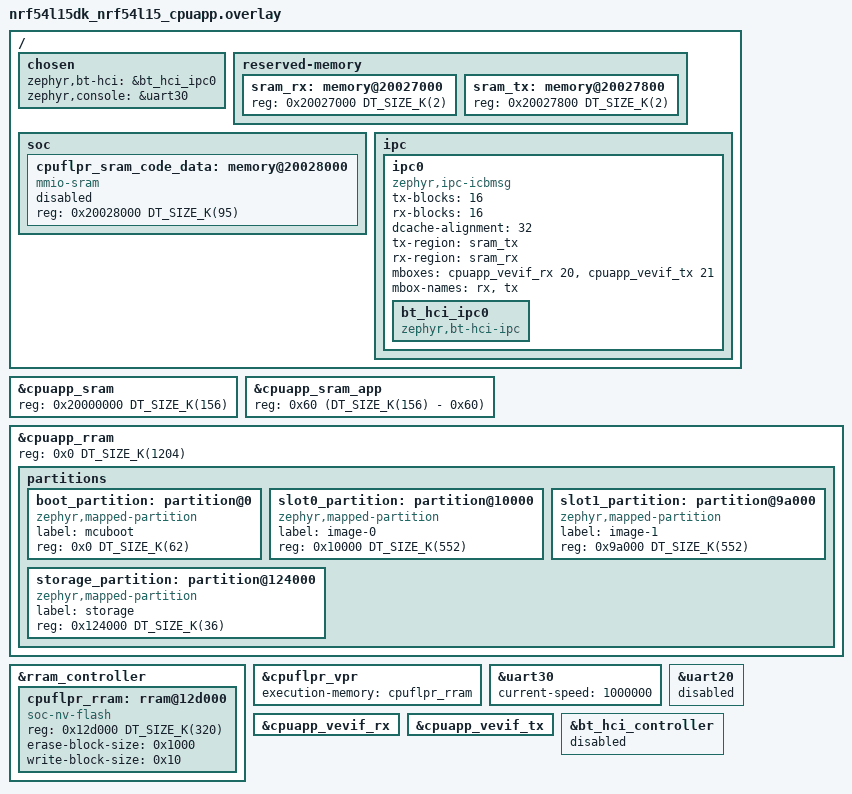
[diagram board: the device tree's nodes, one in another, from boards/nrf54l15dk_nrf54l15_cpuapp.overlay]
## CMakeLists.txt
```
# SPDX-License-Identifier: Apache-2.0

cmake_minimum_required(VERSION 3.28.0)
find_package(Zephyr REQUIRED HINTS $ENV{ZEPHYR_BASE})
project(central_hr)

FILE(GLOB app_sources src/*.c)
target_sources(app PRIVATE ${app_sources})

zephyr_library_include_directories(${ZEPHYR_BASE}/samples/bluetooth)
```

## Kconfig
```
# Copyright 2024 Nordic Semiconductor ASA
# SPDX-License-Identifier: Apache-2.0

if "$(FILE_SUFFIX)" = "extended"

# Increase Advertising Data Length, as Complete Local Name too needs to be
# placed in the AUX_ADV_IND PDU compared to when it is placed in ADV_SCAN_IND
# PDU in the case of legacy advertising.
configdefault BT_CTLR_SCAN_DATA_LEN_MAX
	default 36

endif


if "$(FILE_SUFFIX)" = "phy_coded"

# Increase Advertising Data Length, as Complete Local Name too needs to be
# placed in the AUX_ADV_IND PDU compared to when it is placed in ADV_SCAN_IND
# PDU in the case of legacy advertising.
configdefault BT_CTLR_SCAN_DATA_LEN_MAX
	default 36

configdefault BT_CTLR_PHY_CODED
	default y

endif


source "Kconfig"
```

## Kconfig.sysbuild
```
# Copyright 2023-2024 Nordic Semiconductor ASA
# SPDX-License-Identifier: Apache-2.0

source "share/sysbuild/Kconfig"

config NET_CORE_BOARD
	string
	default "nrf5340dk/nrf5340/cpunet" if "$(BOARD)" = "nrf5340dk"
	default "nrf5340_audio_dk/nrf5340/cpunet" if "$(BOARD)" = "nrf5340_audio_dk"
	default "nrf5340bsim_nrf5340_cpunet" if "$(BOARD)" = "nrf5340bsim_nrf5340_cpuapp"

config NET_CORE_IMAGE_HCI_IPC
	bool "HCI IPC image on network core"
	default y
	depends on NET_CORE_BOARD != ""
```

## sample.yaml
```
sample:
  name: Bluetooth Central HR
tests:
  sample.bluetooth.central_hr:
    arch_allow: x86
    harness: bluetooth
    tags: bluetooth
  sample.bluetooth.central_hr.minimal:
    harness: bluetooth
    platform_allow:
      - bbc_microbit
    integration_platforms:
      - bbc_microbit
    extra_args: CONF_FILE=prj_minimal.conf
    tags: bluetooth
  sample.bluetooth.central_hr.bt_ll_sw_split.extended:
    harness: bluetooth
    platform_allow:
      - nrf52_bsim
      - nrf52dk/nrf52832
      - nrf52840dk/nrf52840
    integration_platforms:
      - nrf52_bsim
      - nrf52dk/nrf52832
      - nrf52840dk/nrf52840
    extra_args: EXTRA_CONF_FILE=overlay-extended.conf
    tags: bluetooth
  sample.bluetooth.central_hr.multicore.bt_ll_sw_split.extended:
    harness: bluetooth
    platform_allow:
      - nrf5340bsim/nrf5340/cpuapp
      - nrf5340dk/nrf5340/cpuapp
    integration_platforms:
      - nrf5340bsim/nrf5340/cpuapp
      - nrf5340dk/nrf5340/cpuapp
    extra_args:
      - CONFIG_BT_EXT_ADV=y
    tags: bluetooth
    sysbuild: true
  sample.bluetooth.central_hr.bt_ll_sw_split.phy_coded:
    harness: bluetooth
    platform_allow:
      - nrf52_bsim
      - nrf52dk/nrf52832
      - nrf52840dk/nrf52840
    integration_platforms:
      - nrf52_bsim
      - nrf52dk/nrf52832
      - nrf52840dk/nrf52840
    extra_args: EXTRA_CONF_FILE=overlay-phy_coded.conf
    tags: bluetooth
  sample.bluetooth.central_hr.multicore.bt_ll_sw_split.phy_coded:
    harness: bluetooth
    platform_allow:
      - nrf5340bsim/nrf5340/cpuapp
      - nrf5340dk/nrf5340/cpuapp
    integration_platforms:
      - nrf5340bsim/nrf5340/cpuapp
      - nrf5340dk/nrf5340/cpuapp
    extra_args:
      - CONFIG_BT_EXT_ADV=y
      - CONFIG_BT_AUTO_PHY_CENTRAL_NONE=y
    tags: bluetooth
    sysbuild: true
```

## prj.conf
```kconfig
CONFIG_BT=y
CONFIG_LOG=y
CONFIG_BT_CENTRAL=y
CONFIG_BT_SMP=y
CONFIG_BT_GATT_CLIENT=y
```

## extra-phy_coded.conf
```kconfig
CONFIG_BT_EXT_ADV=y

# Enable Coded PHY support
CONFIG_BT_CTLR_PHY_CODED=y

# Disable auto PHY update, to switch to 2M PHY
CONFIG_BT_AUTO_PHY_CENTRAL_NONE=y

# Increase Scan Data Length, as Complete Local Name is placed in the
# AUX_ADV_IND PDU compared to when it is placed in ADV_SCAN_IND PDU in the case
# of legacy advertising.
CONFIG_BT_CTLR_SCAN_DATA_LEN_MAX=36
```

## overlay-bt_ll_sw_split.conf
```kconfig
# Configuration file to be used as an overlay to the hci_ipc sample for multi-core boards

CONFIG_BT_EXT_ADV=y

# Enable Coded PHY support
CONFIG_BT_CTLR_PHY_CODED=y

# Increase Advertising Data Length, as Complete Local Name too needs to be
# placed in the AUX_ADV_IND PDU compared to when it is placed in ADV_SCAN_IND
# PDU in the case of legacy advertising.
CONFIG_BT_CTLR_SCAN_DATA_LEN_MAX=36
```

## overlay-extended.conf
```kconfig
CONFIG_BT_EXT_ADV=y

# Increase Scan Data Length, as Complete Local Name is placed in the
# AUX_ADV_IND PDU compared to when it is placed in ADV_SCAN_IND PDU in the case
# of legacy advertising.
CONFIG_BT_CTLR_SCAN_DATA_LEN_MAX=36
```

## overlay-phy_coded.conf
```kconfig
CONFIG_BT_EXT_ADV=y

# Enable Coded PHY support
CONFIG_BT_CTLR_PHY_CODED=y

# Disable auto PHY update, to switch to 2M PHY
CONFIG_BT_AUTO_PHY_UPDATE=n

# Increase Scan Data Length, as Complete Local Name is placed in the
# AUX_ADV_IND PDU compared to when it is placed in ADV_SCAN_IND PDU in the case
# of legacy advertising.
CONFIG_BT_CTLR_SCAN_DATA_LEN_MAX=36
```

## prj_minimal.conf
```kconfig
CONFIG_BT=y
CONFIG_BT_SMP=y
CONFIG_BT_CENTRAL=y
CONFIG_BT_GATT_CLIENT=y

# Drivers and peripherals
CONFIG_I2C=n
CONFIG_WATCHDOG=n
CONFIG_PINCTRL=n
CONFIG_SPI=n
CONFIG_GPIO=n
CONFIG_SERIAL=n

# Power management
CONFIG_PM=n

# Interrupts
CONFIG_DYNAMIC_INTERRUPTS=n
CONFIG_IRQ_OFFLOAD=n

# Memory protection
CONFIG_THREAD_STACK_INFO=n
CONFIG_THREAD_CUSTOM_DATA=n
CONFIG_FPU=n

# Boot
CONFIG_BOOT_BANNER=n
CONFIG_BOOT_DELAY=0

# Console
CONFIG_CONSOLE=n
CONFIG_UART_CONSOLE=n
CONFIG_STDOUT_CONSOLE=n
CONFIG_PRINTK=n
CONFIG_EARLY_CONSOLE=n

# Build
CONFIG_SIZE_OPTIMIZATIONS=y

# ARM
CONFIG_ARM_MPU=n

# In order to correctly tune the stack sizes for the threads the following
# Configurations can enabled to print the current use:
# CONFIG_THREAD_NAME=y
# CONFIG_THREAD_ANALYZER=y
# CONFIG_THREAD_ANALYZER_AUTO=y
# CONFIG_THREAD_ANALYZER_RUN_UNLOCKED=y
# CONFIG_THREAD_ANALYZER_USE_PRINTK=y
# CONFIG_THREAD_ANALYZER_AUTO_INTERVAL=20
# CONFIG_CONSOLE=y
# CONFIG_UART_CONSOLE=y
# CONFIG_SERIAL=y
# CONFIG_PRINTK=y

# Example output of thread analyzer
# BT RX               : STACK: unused 576 usage 448 / 1024 (43 %); CPU: 0 %
# BT RX pri           : STACK: unused 260 usage 188 / 448 (41 %); CPU: 0 %
# BT ECC              : STACK: unused 256 usage 888 / 1144 (77 %); CPU: 1 %
# BT TX               : STACK: unused 296 usage 344 / 640 (53 %); CPU: 0 %
# thread_analyzer     : STACK: unused 128 usage 384 / 512 (75 %); CPU: 1 %
# sysworkq            : STACK: unused 856 usage 168 / 1024 (16 %); CPU: 0 %
# logging             : STACK: unused 232 usage 536 / 768 (69 %); CPU: 0 %
# idle 00             : STACK: unused 208 usage 48 / 256 (18 %); CPU: 97 %
# main                : STACK: unused 576 usage 448 / 1024 (43 %); CPU: 0 %
CONFIG_BT_RX_STACK_SIZE=1024
CONFIG_BT_HCI_TX_STACK_SIZE_WITH_PROMPT=y
CONFIG_BT_HCI_TX_STACK_SIZE=640
CONFIG_IDLE_STACK_SIZE=128
CONFIG_MAIN_STACK_SIZE=640
CONFIG_ISR_STACK_SIZE=1024

# Disable features not needed
CONFIG_TIMESLICING=n
CONFIG_COMMON_LIBC_MALLOC=n
CONFIG_LOG=n
CONFIG_ASSERT=n

# Disable Bluetooth features not needed
# CONFIG_BT_DEBUG_NONE=y
CONFIG_BT_ASSERT=n
CONFIG_BT_DATA_LEN_UPDATE=n
CONFIG_BT_PHY_UPDATE=n
CONFIG_BT_GATT_CACHING=n
CONFIG_BT_GATT_SERVICE_CHANGED=n
CONFIG_BT_GAP_PERIPHERAL_PREF_PARAMS=n
CONFIG_BT_SETTINGS_CCC_LAZY_LOADING=y
CONFIG_BT_HCI_VS=n
CONFIG_BT_CONN_DYNAMIC_CALLBACKS=n

# Disable Bluetooth controller features not needed
CONFIG_BT_CTLR_PRIVACY=n
CONFIG_BT_CTLR_PHY_2M=n
# The sample scans without duplicate filtering
CONFIG_BT_CTLR_DUP_FILTER_LEN=0

# Reduce Bluetooth buffers
CONFIG_BT_BUF_EVT_DISCARDABLE_COUNT=1
CONFIG_BT_BUF_EVT_DISCARDABLE_SIZE=45
CONFIG_BT_BUF_EVT_RX_COUNT=4

CONFIG_BT_L2CAP_TX_BUF_COUNT=2
CONFIG_BT_CTLR_RX_BUFFERS=1
CONFIG_BT_BUF_ACL_TX_COUNT=3
CONFIG_BT_BUF_ACL_TX_SIZE=27

# Limit the number of key slots in PSA Crypto core to reduce
# RAM footprint. Each key the Host uses lives for one operation only: at
# most one key pair, for generating the public key or a DH key, and one
# short-lived key of a pairing computation exist at a time, as nothing
# else in this configuration uses the key store. Three slots leave one
# to spare.
CONFIG_MBEDTLS_PSA_KEY_SLOT_COUNT=3

# This is required because otherwise there won't be
# __heap_start/__heap_end symbols defined in the build. This
# is due to Mbed TLS which at boot uses standard calloc/free
# functions and only after the initialization done from Zephyr
# it switches to its internal memory management functions.
CONFIG_COMMON_LIBC_MALLOC=y
```

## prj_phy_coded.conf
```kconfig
CONFIG_BT_EXT_ADV=y

# Disable auto PHY update, to switch to 2M PHY
CONFIG_BT_AUTO_PHY_UPDATE=n
```

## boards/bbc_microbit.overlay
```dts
/*
 * SPDX-FileCopyrightText: Copyright (c) 2026 Silicon Laboratories Inc.
 * SPDX-License-Identifier: Apache-2.0
 */

/* The sample does not use the accelerometer. With its node enabled the driver
 * is built in as soon as the sensor subsystem is on, which the clock
 * calibration turns on, and brings the I2C driver with it.
 */
&mma8653fc {
	status = "disabled";
};
```

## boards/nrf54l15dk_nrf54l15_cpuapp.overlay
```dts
/*
 * Copyright (c) 2026 Nordic Semiconductor ASA
 *
 * SPDX-License-Identifier: Apache-2.0
 */

/*
 * Must match samples/bluetooth/hci_ipc/boards/nrf54l15dk_nrf54l15_cpuflpr.overlay
 *
 * RRAM: 1204 (APP) + 320 (FLPR) = 1524KB
 * RAM:  156 (APP) + 4 (IPC) + 95 (FLPR) + 1 (unused) = 256KB
 */

/ {
	chosen {
		zephyr,bt-hci = &bt_hci_ipc0;
		zephyr,console = &uart30;
	};

	reserved-memory {
		sram_rx: memory@20027000 {
			reg = <0x20027000 DT_SIZE_K(2)>;
		};

		sram_tx: memory@20027800 {
			reg = <0x20027800 DT_SIZE_K(2)>;
		};
	};

	soc {
		cpuflpr_sram_code_data: memory@20028000 {
			compatible = "mmio-sram";
			reg = <0x20028000 DT_SIZE_K(95)>;
			ranges = <0x0 0x20028000 DT_SIZE_K(95)>;
			status = "reserved";
			#address-cells = <1>;
			#size-cells = <1>;
		};
	};

	ipc {
		ipc0: ipc0 {
			compatible = "zephyr,ipc-icbmsg";
			tx-blocks = <16>;
			rx-blocks = <16>;
			dcache-alignment = <32>;
			tx-region = <&sram_tx>;
			rx-region = <&sram_rx>;
			mboxes = <&cpuapp_vevif_rx 20>, <&cpuapp_vevif_tx 21>;
			mbox-names = "rx", "tx";
			status = "okay";

			bt_hci_ipc0: bt_hci_ipc0 {
				compatible = "zephyr,bt-hci-ipc";
				status = "okay";
			};
		};
	};
};

&cpuapp_sram {
	reg = <0x20000000 DT_SIZE_K(156)>;
	ranges = <0x0 0x20000000 DT_SIZE_K(156)>;
};

&cpuapp_sram_app {
	reg = <0x60 (DT_SIZE_K(156) - 0x60)>;
};

&cpuapp_rram {
	reg = <0x0 DT_SIZE_K(1204)>;
	ranges = <0x0 0x0 DT_SIZE_K(1204)>;

	/delete-node/ partitions;

	partitions {
		ranges;
		#address-cells = <1>;
		#size-cells = <1>;

		boot_partition: partition@0 {
			compatible = "zephyr,mapped-partition";
			label = "mcuboot";
			reg = <0x0 DT_SIZE_K(62)>;
		};

		slot0_partition: partition@10000 {
			compatible = "zephyr,mapped-partition";
			label = "image-0";
			reg = <0x10000 DT_SIZE_K(552)>;
		};

		slot1_partition: partition@9a000 {
			compatible = "zephyr,mapped-partition";
			label = "image-1";
			reg = <0x9a000 DT_SIZE_K(552)>;
		};

		storage_partition: partition@124000 {
			compatible = "zephyr,mapped-partition";
			label = "storage";
			reg = <0x124000 DT_SIZE_K(36)>;
		};
	};
};

&rram_controller {
	cpuflpr_rram: rram@12d000 {
		compatible = "soc-nv-flash";
		reg = <0x12d000 DT_SIZE_K(320)>;
		ranges = <0x0 0x12d000 DT_SIZE_K(320)>;
		erase-block-size = <0x1000>;
		write-block-size = <0x10>;
		#address-cells = <1>;
		#size-cells = <1>;
	};
};

&cpuflpr_vpr {
	status = "okay";
	execution-memory = <&cpuflpr_rram>;
	/*
	 * execution-memory = <&cpuflpr_sram_code_data>;
	 * source-memory = <&cpuflpr_rram>;
	 */
};

&uart30 {
	current-speed = <1000000>;
	status = "okay";
};

&uart20 {
	status = "disabled";
};

&cpuapp_vevif_rx {
	status = "okay";
};

&cpuapp_vevif_tx {
	status = "okay";
};

&bt_hci_controller {
	status = "disabled";
};
```

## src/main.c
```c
/* main.c - Application main entry point */

/*
 * Copyright (c) 2015-2016 Intel Corporation
 *
 * SPDX-License-Identifier: Apache-2.0
 */

#include <zephyr/types.h>
#include <stddef.h>
#include <errno.h>
#include <zephyr/kernel.h>
#include <zephyr/sys/printk.h>

#include <zephyr/bluetooth/bluetooth.h>
#include <zephyr/bluetooth/hci.h>
#include <zephyr/bluetooth/conn.h>
#include <zephyr/bluetooth/uuid.h>
#include <zephyr/bluetooth/gatt.h>
#include <zephyr/sys/byteorder.h>

static void start_scan(void);

static struct bt_conn *default_conn;

static struct bt_uuid_16 discover_uuid = BT_UUID_INIT_16(0);
static struct bt_gatt_discover_params discover_params;
static struct bt_gatt_subscribe_params subscribe_params;

uint64_t total_rx_count; /* This value is exposed to test code */

static uint8_t notify_func(struct bt_conn *conn,
			   struct bt_gatt_subscribe_params *params,
			   const void *data, uint16_t length)
{
	if (!data) {
		printk("[UNSUBSCRIBED]\n");
		params->value_handle = 0U;
		return BT_GATT_ITER_STOP;
	}

	printk("[NOTIFICATION] data %p length %u\n", data, length);

	total_rx_count++;

	return BT_GATT_ITER_CONTINUE;
}

static uint8_t discover_func(struct bt_conn *conn,
			     const struct bt_gatt_attr *attr,
			     struct bt_gatt_discover_params *params)
{
	int err;

	if (!attr) {
		printk("Discover complete\n");
		(void)memset(params, 0, sizeof(*params));
		return BT_GATT_ITER_STOP;
	}

	printk("[ATTRIBUTE] handle %u\n", attr->handle);

	if (!bt_uuid_cmp(discover_params.uuid, BT_UUID_HRS)) {
		memcpy(&discover_uuid, BT_UUID_HRS_MEASUREMENT, sizeof(discover_uuid));
		discover_params.uuid = &discover_uuid.uuid;
		discover_params.start_handle = attr->handle + 1;
		discover_params.type = BT_GATT_DISCOVER_CHARACTERISTIC;

		err = bt_gatt_discover(conn, &discover_params);
		if (err) {
			printk("Discover failed (err %d)\n", err);
		}
	} else if (!bt_uuid_cmp(discover_params.uuid,
				BT_UUID_HRS_MEASUREMENT)) {
		memcpy(&discover_uuid, BT_UUID_GATT_CCC, sizeof(discover_uuid));
		discover_params.uuid = &discover_uuid.uuid;
		discover_params.start_handle = attr->handle + 2;
		discover_params.type = BT_GATT_DISCOVER_DESCRIPTOR;
		subscribe_params.value_handle = bt_gatt_attr_value_handle(attr);

		err = bt_gatt_discover(conn, &discover_params);
		if (err) {
			printk("Discover failed (err %d)\n", err);
		}
	} else {
		subscribe_params.notify = notify_func;
		subscribe_params.value = BT_GATT_CCC_NOTIFY;
		subscribe_params.ccc_handle = attr->handle;

		err = bt_gatt_subscribe(conn, &subscribe_params);
		if (err && err != -EALREADY) {
			printk("Subscribe failed (err %d)\n", err);
		} else {
			printk("[SUBSCRIBED]\n");
		}

		return BT_GATT_ITER_STOP;
	}

	return BT_GATT_ITER_STOP;
}

static bool eir_found(struct bt_data *data, void *user_data)
{
	bt_addr_le_t *addr = user_data;
	int i;

	printk("[AD]: %u data_len %u\n", data->type, data->data_len);

	switch (data->type) {
	case BT_DATA_UUID16_SOME:
	case BT_DATA_UUID16_ALL:
		if (data->data_len % sizeof(uint16_t) != 0U) {
			printk("AD malformed\n");
			return true;
		}

		for (i = 0; i < data->data_len; i += sizeof(uint16_t)) {
			struct bt_conn_le_create_param *create_param;
			struct bt_le_conn_param *param;
			const struct bt_uuid *uuid;
			uint16_t u16;
			int err;

			memcpy(&u16, &data->data[i], sizeof(u16));
			uuid = BT_UUID_DECLARE_16(sys_le16_to_cpu(u16));
			if (bt_uuid_cmp(uuid, BT_UUID_HRS)) {
				continue;
			}

			err = bt_le_scan_stop();
			if (err) {
				printk("Stop LE scan failed (err %d)\n", err);
				continue;
			}

			printk("Creating connection with Coded PHY support\n");
			param = BT_LE_CONN_PARAM_DEFAULT;
			create_param = BT_CONN_LE_CREATE_CONN;
			create_param->options |= BT_CONN_LE_OPT_CODED;
			err = bt_conn_le_create(addr, create_param, param,
						&default_conn);
			if (err) {
				printk("Create connection with Coded PHY support failed (err %d)\n",
				       err);

				printk("Creating non-Coded PHY connection\n");
				create_param->options &= ~BT_CONN_LE_OPT_CODED;
				err = bt_conn_le_create(addr, create_param,
							param, &default_conn);
				if (err) {
					printk("Create connection failed (err %d)\n", err);
					start_scan();
				}
			}

			return false;
		}
	}

	return true;
}

static void device_found(const bt_addr_le_t *addr, int8_t rssi, uint8_t type,
			 struct net_buf_simple *ad)
{
	printk("[DEVICE]: %s, AD evt type %u, AD data len %u, RSSI %i\n",
	       bt_addr_le_str(addr), type, ad->len, rssi);

	/* We're only interested in legacy connectable events or
	 * possible extended advertising that are connectable.
	 */
	if (type == BT_GAP_ADV_TYPE_ADV_IND ||
	    type == BT_GAP_ADV_TYPE_ADV_DIRECT_IND ||
	    type == BT_GAP_ADV_TYPE_EXT_ADV) {
		bt_data_parse(ad, eir_found, (void *)addr);
	}
}

static void start_scan(void)
{
	int err;

	/* Use active scanning and disable duplicate filtering to handle any
	 * devices that might update their advertising data at runtime. */
	struct bt_le_scan_param scan_param = {
		.type       = BT_LE_SCAN_TYPE_ACTIVE,
		.options    = BT_LE_SCAN_OPT_CODED,
		.interval   = BT_GAP_SCAN_FAST_INTERVAL,
		.window     = BT_GAP_SCAN_FAST_WINDOW,
	};

	err = bt_le_scan_start(&scan_param, device_found);
	if (err) {
		printk("Scanning with Coded PHY support failed (err %d)\n", err);

		printk("Scanning without Coded PHY\n");
		scan_param.options &= ~BT_LE_SCAN_OPT_CODED;
		err = bt_le_scan_start(&scan_param, device_found);
		if (err) {
			printk("Scanning failed to start (err %d)\n", err);
			return;
		}
	}

	printk("Scanning successfully started\n");
}

static void connected(struct bt_conn *conn, uint8_t conn_err)
{
	int err;

	if (conn_err) {
		printk("Failed to connect to %s (%u)\n", bt_conn_dst_str(conn), conn_err);

		bt_conn_drop(&default_conn);

		start_scan();
		return;
	}

	printk("Connected: %s\n", bt_conn_dst_str(conn));

	total_rx_count = 0U;

	if (conn == default_conn) {
		memcpy(&discover_uuid, BT_UUID_HRS, sizeof(discover_uuid));
		discover_params.uuid = &discover_uuid.uuid;
		discover_params.func = discover_func;
		discover_params.start_handle = BT_ATT_FIRST_ATTRIBUTE_HANDLE;
		discover_params.end_handle = BT_ATT_LAST_ATTRIBUTE_HANDLE;
		discover_params.type = BT_GATT_DISCOVER_PRIMARY;

		err = bt_gatt_discover(default_conn, &discover_params);
		if (err) {
			printk("Discover failed(err %d)\n", err);
			return;
		}
	}
}

static void disconnected(struct bt_conn *conn, uint8_t reason)
{
	printk("Disconnected: %s, reason 0x%02x %s\n", bt_conn_dst_str(conn),
	       reason, bt_hci_err_to_str(reason));

	if (default_conn != conn) {
		return;
	}

	bt_conn_drop(&default_conn);

	start_scan();
}

BT_CONN_CB_DEFINE(conn_callbacks) = {
	.connected = connected,
	.disconnected = disconnected,
};

int main(void)
{
	int err;
	err = bt_enable(NULL);

	if (err) {
		printk("Bluetooth init failed (err %d)\n", err);
		return 0;
	}

	printk("Bluetooth initialized\n");

	start_scan();
	return 0;
}
```
